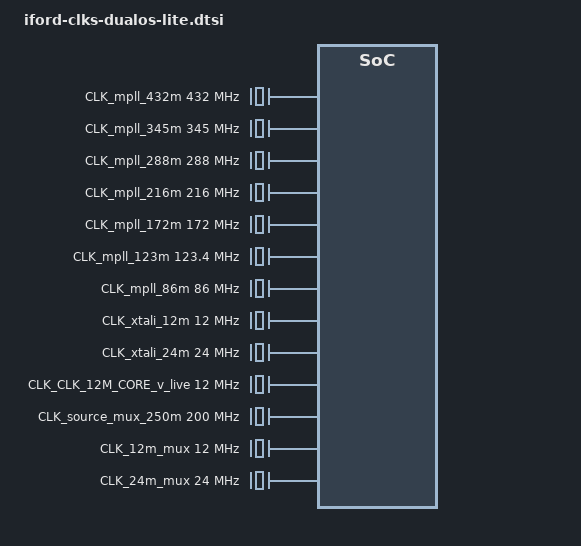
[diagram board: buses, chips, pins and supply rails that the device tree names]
/*
* iford-clks.dtsi- Sigmastar
*
* Copyright (c) [2019~2020] SigmaStar Technology.
*
*
* This software is licensed under the terms of the GNU General Public
* License version 2, as published by the Free Software Foundation, and
* may be copied, distributed, and modified under those terms.
*
* This program is distributed in the hope that it will be useful,
* but WITHOUT ANY WARRANTY; without even the implied warranty of
* MERCHANTABILITY or FITNESS FOR A PARTICULAR PURPOSE.  See the
* GNU General Public License version 2 for more details.
*
*/

/* generated by CLK_DT_GEN_5.2 */
/* CLK FILENAME: iford\iford_clock_table.xls */
/* REG FILENAME: iford\iford_reg_CLKGEN.xls, ifordw\iford_reg_CLKGEN2.xls, iford\iford_reg_pm_sleep.xls, iford\iford_reg_block.xls, iford\ifordw_reg_chiptop.xls */

CLK_VOID: CLK_VOID {
    #clock-cells = <0>;
    compatible = "fixed-clock";
    clock-frequency = <1>;
};

CLK_upll_480m: CLK_upll_480m {
    #clock-cells = <0>;
    compatible = "sstar,complex-clock";
    clocks = <&CLK_upll_960m>;
};

CLK_mpll_432m: CLK_mpll_432m {
    #clock-cells = <0>;
    compatible = "fixed-clock";
    clock-frequency = <432000000>;
};

CLK_upll_384m: CLK_upll_384m {
    #clock-cells = <0>;
    compatible = "sstar,complex-clock";
    clocks = <&CLK_upll_960m>;
};

CLK_mpll_345m: CLK_mpll_345m {
    #clock-cells = <0>;
    compatible = "fixed-clock";
    clock-frequency = <345000000>;
};

CLK_upll_320m: CLK_upll_320m {
    #clock-cells = <0>;
    compatible = "sstar,complex-clock";
    clocks = <&CLK_upll_960m>;
};

CLK_mpll_288m: CLK_mpll_288m {
    #clock-cells = <0>;
    compatible = "fixed-clock";
    clock-frequency = <288000000>;
};

CLK_mpll_216m: CLK_mpll_216m {
    #clock-cells = <0>;
    compatible = "fixed-clock";
    clock-frequency = <216000000>;
};

CLK_mpll_172m: CLK_mpll_172m {
    #clock-cells = <0>;
    compatible = "fixed-clock";
    clock-frequency = <172000000>;
};

CLK_mpll_123m: CLK_mpll_123m {
    #clock-cells = <0>;
    compatible = "fixed-clock";
    clock-frequency = <123400000>;
};

CLK_mpll_86m: CLK_mpll_86m {
    #clock-cells = <0>;
    compatible = "fixed-clock";
    clock-frequency = <86000000>;
};

CLK_upll_480m_div2: CLK_upll_480m_div2 {
    #clock-cells = <0>;
    compatible = "fixed-factor-clock";
    clocks = <&CLK_upll_480m>;
    clock-div = <2>;
    clock-mult = <1>;
};

CLK_upll_384m_div2: CLK_upll_384m_div2 {
    #clock-cells = <0>;
    compatible = "fixed-factor-clock";
    clocks = <&CLK_upll_384m>;
    clock-div = <2>;
    clock-mult = <1>;
};

CLK_upll_320m_div2: CLK_upll_320m_div2 {
    #clock-cells = <0>;
    compatible = "fixed-factor-clock";
    clocks = <&CLK_upll_320m>;
    clock-div = <2>;
    clock-mult = <1>;
};

CLK_mpll_288m_div2: CLK_mpll_288m_div2 {
    #clock-cells = <0>;
    compatible = "fixed-factor-clock";
    clocks = <&CLK_mpll_288m>;
    clock-div = <2>;
    clock-mult = <1>;
};

CLK_mpll_288m_div4: CLK_mpll_288m_div4 {
    #clock-cells = <0>;
    compatible = "fixed-factor-clock";
    clocks = <&CLK_mpll_288m>;
    clock-div = <4>;
    clock-mult = <1>;
};

CLK_mpll_288m_div8: CLK_mpll_288m_div8 {
    #clock-cells = <0>;
    compatible = "fixed-factor-clock";
    clocks = <&CLK_mpll_288m>;
    clock-div = <8>;
    clock-mult = <1>;
};

CLK_mpll_432m_div4: CLK_mpll_432m_div4 {
    #clock-cells = <0>;
    compatible = "fixed-factor-clock";
    clocks = <&CLK_mpll_432m>;
    clock-div = <4>;
    clock-mult = <1>;
};

CLK_mpll_432m_div8: CLK_mpll_432m_div8 {
    #clock-cells = <0>;
    compatible = "fixed-factor-clock";
    clocks = <&CLK_mpll_432m>;
    clock-div = <8>;
    clock-mult = <1>;
};

CLK_mpll_432m_div16: CLK_mpll_432m_div16 {
    #clock-cells = <0>;
    compatible = "fixed-factor-clock";
    clocks = <&CLK_mpll_432m>;
    clock-div = <16>;
    clock-mult = <1>;
};

CLK_mpll_123m_div2: CLK_mpll_123m_div2 {
    #clock-cells = <0>;
    compatible = "fixed-factor-clock";
    clocks = <&CLK_mpll_123m>;
    clock-div = <2>;
    clock-mult = <1>;
};

CLK_mpll_86m_div2: CLK_mpll_86m_div2 {
    #clock-cells = <0>;
    compatible = "fixed-factor-clock";
    clocks = <&CLK_mpll_86m>;
    clock-div = <2>;
    clock-mult = <1>;
};

CLK_mpll_86m_div4: CLK_mpll_86m_div4 {
    #clock-cells = <0>;
    compatible = "fixed-factor-clock";
    clocks = <&CLK_mpll_86m>;
    clock-div = <4>;
    clock-mult = <1>;
};

CLK_mpll_86m_div16: CLK_mpll_86m_div16 {
    #clock-cells = <0>;
    compatible = "fixed-factor-clock";
    clocks = <&CLK_mpll_86m>;
    clock-div = <16>;
    clock-mult = <1>;
};

CLK_upll_384m_div8: CLK_upll_384m_div8 {
    #clock-cells = <0>;
    compatible = "fixed-factor-clock";
    clocks = <&CLK_upll_384m>;
    clock-div = <8>;
    clock-mult = <1>;
};

CLK_upll_320m_div8: CLK_upll_320m_div8 {
    #clock-cells = <0>;
    compatible = "fixed-factor-clock";
    clocks = <&CLK_upll_320m>;
    clock-div = <8>;
    clock-mult = <1>;
#if !IS_ENABLED(CONFIG_SSTAR_SDMMC)
    status = "disabled";
#endif
};

CLK_upll_320m_div10: CLK_upll_320m_div10 {
    #clock-cells = <0>;
    compatible = "fixed-factor-clock";
    clocks = <&CLK_upll_320m>;
    clock-div = <10>;
    clock-mult = <1>;
#if !IS_ENABLED(CONFIG_SSTAR_SDMMC)
    status = "disabled";
#endif
};

CLK_upll_320m_div16: CLK_upll_320m_div16 {
    #clock-cells = <0>;
    compatible = "fixed-factor-clock";
    clocks = <&CLK_upll_320m>;
    clock-div = <16>;
    clock-mult = <1>;
#if !IS_ENABLED(CONFIG_SSTAR_SDMMC)
    status = "disabled";
#endif

};

CLK_disppll_clk: CLK_disppll_clk {
    #clock-cells = <0>;
    compatible = "sstar,complex-clock";
    clocks = <&CLK_mpll_432m>;
};

CLK_disppll_clk_div2: CLK_disppll_clk_div2 {
    #clock-cells = <0>;
    compatible = "fixed-factor-clock";
    clocks = <&CLK_disppll_clk>;
    clock-div = <2>;
    clock-mult = <1>;
};

CLK_xtali_12m: CLK_xtali_12m {
    #clock-cells = <0>;
    compatible = "fixed-clock";
    clock-frequency = <12000000>;
};

CLK_xtali_12m_div8: CLK_xtali_12m_div8 {
    #clock-cells = <0>;
    compatible = "fixed-factor-clock";
    clocks = <&CLK_xtali_12m>;
    clock-div = <8>;
    clock-mult = <1>;
};

CLK_xtali_12m_div16: CLK_xtali_12m_div16 {
    #clock-cells = <0>;
    compatible = "fixed-factor-clock";
    clocks = <&CLK_xtali_12m>;
    clock-div = <16>;
    clock-mult = <1>;
};

CLK_xtali_12m_div40: CLK_xtali_12m_div40 {
    #clock-cells = <0>;
    compatible = "fixed-factor-clock";
    clocks = <&CLK_xtali_12m>;
    clock-div = <40>;
    clock-mult = <1>;
};

CLK_xtali_12m_div64: CLK_xtali_12m_div64 {
    #clock-cells = <0>;
    compatible = "fixed-factor-clock";
    clocks = <&CLK_xtali_12m>;
    clock-div = <64>;
    clock-mult = <1>;
};

CLK_xtali_12m_div128: CLK_xtali_12m_div128 {
    #clock-cells = <0>;
    compatible = "fixed-factor-clock";
    clocks = <&CLK_xtali_12m>;
    clock-div = <128>;
    clock-mult = <1>;
};

CLK_xtali_24m: CLK_xtali_24m {
    #clock-cells = <0>;
    compatible = "fixed-clock";
    clock-frequency = <24000000>;
};

CLK_CLK_12M_CORE_v_live: CLK_CLK_12M_CORE_v_live {
    #clock-cells = <0>;
    compatible = "fixed-clock";
    clock-frequency = <12000000>;
};

CLK_ipupll_clk: CLK_ipupll_clk {
    #clock-cells = <0>;
    compatible = "sstar,complex-clock";
    clocks = <&CLK_mpll_432m>;
};

CLK_miupll_clk: CLK_miupll_clk {
    #clock-cells = <0>;
    compatible = "sstar,complex-clock";
    clocks = <&CLK_xtali_24m>;
};

CLK_cpu_pll: CLK_cpu_pll {
    #clock-cells = <0>;
    compatible = "sstar,complex-clock";
    clocks = <&CLK_mpll_432m>;
};

CLK_armpll_37p125m: CLK_armpll_37p125m {
    #clock-cells = <0>;
    compatible = "sstar,complex-clock";
    clocks = <&CLK_cpu_pll>;
};

CLK_spi_synth_pll: CLK_spi_synth_pll {
    #clock-cells = <0>;
    compatible = "sstar,complex-clock";
    clocks = <&CLK_mpll_432m>;
};

CLK_fuart_synth_out: CLK_fuart_synth_out {
    #clock-cells = <0>;
    compatible = "sstar,complex-clock";
    clocks = <&CLK_fuart_synth_in>;
};

CLK_fuart0_synth_out: CLK_fuart0_synth_out {
    #clock-cells = <0>;
    compatible = "sstar,complex-clock";
    clocks = <&CLK_fuart0_synth_in>;
};

CLK_fuart1_synth_out: CLK_fuart1_synth_out {
    #clock-cells = <0>;
    compatible = "sstar,complex-clock";
    clocks = <&CLK_fuart1_synth_in>;
};

CLK_miu_p: CLK_miu_p {
    #clock-cells = <0>;
    compatible = "fixed-factor-clock";
    clocks = <&CLK_miupll_clk>;
    clock-div = <1>;
    clock-mult = <1>;
};

CLK_mspi0_p: CLK_mspi0_p {
    #clock-cells = <0>;
    compatible = "fixed-factor-clock";
    clocks = <&CLK_mspi0>;
    clock-div = <1>;
    clock-mult = <1>;
#if !IS_ENABLED(CONFIG_SSTAR_MSPI)
    status = "disabled";
#endif
};

CLK_mcu_p: CLK_mcu_p {
    #clock-cells = <0>;
    compatible = "fixed-factor-clock";
    clocks = <&CLK_mcu>;
    clock-div = <1>;
    clock-mult = <1>;
};

CLK_mcu_pm_p: CLK_mcu_pm_p {
    #clock-cells = <0>;
    compatible = "fixed-factor-clock";
    clocks = <&CLK_mcu_pm>;
    clock-div = <1>;
    clock-mult = <1>;
};

CLK_otp_p: CLK_otp_p {
    #clock-cells = <0>;
    compatible = "fixed-clock";
    clock-frequency = <12000000>;
};

CLK_bist_pm_p: CLK_bist_pm_p {
    #clock-cells = <0>;
    compatible = "fixed-clock";
    clock-frequency = <192000000>;
};

CLK_emac_testrx125_in_lan: CLK_emac_testrx125_in_lan {
    #clock-cells = <0>;
    compatible = "fixed-clock";
    clock-frequency = <125000000>;
};

CLK_source_mux_250m: CLK_source_mux_250m {
    #clock-cells = <0>;
#ifndef  CONFIG_PM_CLK_SRC_24M
    compatible = "fixed-clock";
    clock-frequency = <200000000>;
#else
    // select mpll-216 to replace rtcpll when remove RTC 32K xtal
    compatible = "fixed-factor-clock";
    clocks = <&CLK_mpll_216m>;
    clock-div = <1>;
    clock-mult = <1>;
#endif
};

CLK_source_mux_250m_div2: CLK_source_mux_250m_div2 {
    #clock-cells = <0>;
    compatible = "fixed-factor-clock";
    clocks = <&CLK_source_mux_250m>;
    clock-div = <2>;
    clock-mult = <1>;
};

CLK_source_mux_250m_div4: CLK_source_mux_250m_div4 {
    #clock-cells = <0>;
    compatible = "fixed-factor-clock";
    clocks = <&CLK_source_mux_250m>;
    clock-div = <4>;
    clock-mult = <1>;
};

CLK_source_mux_250m_div5: CLK_source_mux_250m_div5 {
    #clock-cells = <0>;
    compatible = "fixed-factor-clock";
    clocks = <&CLK_source_mux_250m>;
    clock-div = <5>;
    clock-mult = <1>;
};

CLK_source_mux_250m_div6: CLK_source_mux_250m_div6 {
    #clock-cells = <0>;
    compatible = "fixed-factor-clock";
    clocks = <&CLK_source_mux_250m>;
    clock-div = <6>;
    clock-mult = <1>;
};

CLK_source_mux_250m_div8: CLK_source_mux_250m_div8 {
    #clock-cells = <0>;
    compatible = "fixed-factor-clock";
    clocks = <&CLK_source_mux_250m>;
    clock-div = <8>;
    clock-mult = <1>;
};

CLK_12m_mux: CLK_12m_mux {
    #clock-cells = <0>;
    compatible = "fixed-clock";
    clock-frequency = <12000000>;
};

CLK_12m_mux_div2: CLK_12m_mux_div2 {
    #clock-cells = <0>;
    compatible = "fixed-factor-clock";
    clocks = <&CLK_12m_mux>;
    clock-div = <2>;
    clock-mult = <1>;
};

CLK_12m_mux_div40: CLK_12m_mux_div40 {
    #clock-cells = <0>;
    compatible = "fixed-factor-clock";
    clocks = <&CLK_12m_mux>;
    clock-div = <40>;
    clock-mult = <1>;
};

CLK_24m_mux: CLK_24m_mux {
    #clock-cells = <0>;
    compatible = "fixed-clock";
    clock-frequency = <24000000>;
};

CLK_ddr_syn: CLK_ddr_syn {
    #clock-cells = <0>;
    compatible = "sstar,composite-clock";
    clocks = <&CLK_mpll_432m>,<&CLK_mpll_216m>,<&CLK_xtali_12m>;
    reg = <REG_CKG_DDR_SYN_BASE 0x4>;
    mux-shift = <2>;  //2+REG_CKG_DDR_SYN_OFFSET
    mux-width = <2>;
    gate-shift = <0>;  //0+REG_CKG_DDR_SYN_OFFSET
    auto-enable = <1>;
};

CLK_miu_rec: CLK_miu_rec {
    #clock-cells = <0>;
    compatible = "sstar,composite-clock";
    clocks = <&CLK_xtali_12m_div8>,<&CLK_xtali_12m_div16>,<&CLK_xtali_12m_div64>,<&CLK_xtali_12m_div128>;
    reg = <REG_CKG_MIU_REC_BASE 0x4>;
    mux-shift = <2>;  //2+REG_CKG_MIU_REC_OFFSET
    mux-width = <2>;
    gate-shift = <0>;  //0+REG_CKG_MIU_REC_OFFSET
    auto-enable = <1>;
};

CLK_mcu: CLK_mcu {
    #clock-cells = <0>;
    compatible = "sstar,composite-clock";
    clocks = <&CLK_mpll_216m>,<&CLK_mpll_288m>,<&CLK_upll_320m>,<&CLK_mpll_432m_div4>,<&CLK_xtali_12m>;
    reg = <REG_CKG_MCU_BASE 0x4>;
    mux-shift = <2>;  //2+REG_CKG_MCU_OFFSET
    mux-width = <2>;
    gate-shift = <0>;  //0+REG_CKG_MCU_OFFSET
    glitch-shift = <4>;  //4+REG_CKG_MCU_OFFSET
    str-ignore;
    auto-enable = <1>;
};

CLK_riubrdg: CLK_riubrdg {
    #clock-cells = <0>;
    compatible = "sstar,composite-clock";
    clocks = <&CLK_mcu_p>;
    reg = <REG_CKG_RIUBRDG_BASE 0x4>;
    mux-shift = <10>;  //2+REG_CKG_RIUBRDG_OFFSET
    mux-width = <2>;
    gate-shift = <8>;  //0+REG_CKG_RIUBRDG_OFFSET
    auto-enable = <1>;
};

CLK_pwm: CLK_pwm {
    #clock-cells = <0>;
    compatible = "sstar,composite-clock";
    clocks = <&CLK_xtali_12m>;
    reg = <REG_CKG_PWM_BASE 0x4>;
    mux-shift = <10>;  //2+REG_CKG_PWM_OFFSET
    mux-width = <3>;
    gate-shift = <8>;  //0+REG_CKG_PWM_OFFSET
    ignore = <1>;
};

CLK_fuart_synth_in: CLK_fuart_synth_in {
    #clock-cells = <0>;
    compatible = "sstar,composite-clock";
    clocks = <&CLK_mpll_432m>,<&CLK_mpll_216m>;
    reg = <REG_CKG_FUART_SYNTH_IN_BASE 0x4>;
    mux-shift = <6>;  //2+REG_CKG_FUART_SYNTH_IN_OFFSET
    mux-width = <2>;
    gate-shift = <4>;  //0+REG_CKG_FUART_SYNTH_IN_OFFSET
    auto-enable = <0>;
};

CLK_fuart0_synth_in: CLK_fuart0_synth_in {
    #clock-cells = <0>;
    compatible = "sstar,composite-clock";
    clocks = <&CLK_mpll_432m>,<&CLK_mpll_216m>;
    reg = <REG_CKG_FUART0_SYNTH_IN_BASE 0x4>;
    mux-shift = <6>;  //2+REG_CKG_FUART0_SYNTH_IN_OFFSET
    mux-width = <2>;
    gate-shift = <4>;  //0+REG_CKG_FUART0_SYNTH_IN_OFFSET
    auto-enable = <0>;
};

CLK_fuart1_synth_in: CLK_fuart1_synth_in {
    #clock-cells = <0>;
    compatible = "sstar,composite-clock";
    clocks = <&CLK_mpll_432m>,<&CLK_mpll_216m>;
    reg = <REG_CKG_FUART1_SYNTH_IN_BASE 0x4>;
    mux-shift = <6>;  //2+REG_CKG_FUART1_SYNTH_IN_OFFSET
    mux-width = <2>;
    gate-shift = <4>;  //0+REG_CKG_FUART1_SYNTH_IN_OFFSET
    auto-enable = <0>;
};

CLK_fuart: CLK_fuart {
    #clock-cells = <0>;
    compatible = "sstar,composite-clock";
    clocks = <&CLK_mpll_172m>,<&CLK_mpll_288m_div2>,<&CLK_xtali_24m>,<&CLK_fuart_synth_out>;
    reg = <REG_CKG_FUART_BASE 0x4>;
    mux-shift = <2>;  //2+REG_CKG_FUART_OFFSET
    mux-width = <2>;
    gate-shift = <0>;  //0+REG_CKG_FUART_OFFSET
    auto-enable = <0>;
};

CLK_fuart0: CLK_fuart0 {
    #clock-cells = <0>;
    compatible = "sstar,composite-clock";
    clocks = <&CLK_mpll_172m>,<&CLK_mpll_288m_div2>,<&CLK_xtali_24m>,<&CLK_fuart0_synth_out>;
    reg = <REG_CKG_FUART0_BASE 0x4>;
    mux-shift = <2>;  //2+REG_CKG_FUART0_OFFSET
    mux-width = <2>;
    gate-shift = <0>;  //0+REG_CKG_FUART0_OFFSET
    auto-enable = <1>;
};

CLK_fuart1: CLK_fuart1 {
    #clock-cells = <0>;
    compatible = "sstar,composite-clock";
    clocks = <&CLK_mpll_172m>,<&CLK_mpll_288m_div2>,<&CLK_xtali_24m>,<&CLK_fuart1_synth_out>;
    reg = <REG_CKG_FUART1_BASE 0x4>;
    mux-shift = <6>;  //2+REG_CKG_FUART1_OFFSET
    mux-width = <2>;
    gate-shift = <4>;  //0+REG_CKG_FUART1_OFFSET
    auto-enable = <0>;
};

CLK_mspi0: CLK_mspi0 {
    #clock-cells = <0>;
    compatible = "sstar,composite-clock";
    clocks = <&CLK_mpll_432m_div4>,<&CLK_mpll_288m_div2>,<&CLK_xtali_12m>,<&CLK_spi_synth_pll>;
    reg = <REG_CKG_MSPI0_BASE 0x4>;
    mux-shift = <2>;  //2+REG_CKG_MSPI0_OFFSET
    mux-width = <2>;
    gate-shift = <0>;  //0+REG_CKG_MSPI0_OFFSET
    auto-enable = <0>;
#if !IS_ENABLED(CONFIG_SSTAR_MSPI)
    status = "disabled";
#endif
};

CLK_miic0: CLK_miic0 {
    #clock-cells = <0>;
    compatible = "sstar,composite-clock";
    clocks = <&CLK_mpll_288m_div4>,<&CLK_mpll_432m_div8>,<&CLK_xtali_12m>;
    reg = <REG_CKG_MIIC0_BASE 0x4>;
    mux-shift = <2>;  //2+REG_CKG_MIIC0_OFFSET
    mux-width = <2>;
    gate-shift = <0>;  //0+REG_CKG_MIIC0_OFFSET
    auto-enable = <0>;
};

CLK_miic1: CLK_miic1 {
    #clock-cells = <0>;
    compatible = "sstar,composite-clock";
    clocks = <&CLK_mpll_288m_div4>,<&CLK_mpll_432m_div8>,<&CLK_xtali_12m>;
    reg = <REG_CKG_MIIC1_BASE 0x4>;
    mux-shift = <10>;  //2+REG_CKG_MIIC1_OFFSET
    mux-width = <2>;
    gate-shift = <8>;  //0+REG_CKG_MIIC1_OFFSET
    auto-enable = <0>;
};

CLK_miic2: CLK_miic2 {
    #clock-cells = <0>;
    compatible = "sstar,composite-clock";
    clocks = <&CLK_mpll_288m_div4>,<&CLK_mpll_432m_div8>,<&CLK_xtali_12m>;
    reg = <REG_CKG_MIIC2_BASE 0x4>;
    mux-shift = <14>;  //2+REG_CKG_MIIC2_OFFSET
    mux-width = <2>;
    gate-shift = <12>;  //0+REG_CKG_MIIC2_OFFSET
    auto-enable = <0>;
};

CLK_pwr_ctl: CLK_pwr_ctl {
    #clock-cells = <0>;
    compatible = "sstar,composite-clock";
    clocks = <&CLK_xtali_12m_div16>,<&CLK_xtali_12m_div8>,<&CLK_xtali_12m>;
    reg = <REG_CKG_PWR_CTL_BASE 0x4>;
    mux-shift = <2>;  //2+REG_CKG_PWR_CTL_OFFSET
    mux-width = <2>;
    gate-shift = <0>;  //0+REG_CKG_PWR_CTL_OFFSET
    auto-enable = <1>;
};

CLK_xtali: CLK_xtali {
    #clock-cells = <0>;
    compatible = "sstar,composite-clock";
    clocks = <&CLK_xtali_12m>;
    reg = <REG_CKG_XTALI_BASE 0x4>;
    mux-shift = <2>;  //2+REG_CKG_XTALI_OFFSET
    mux-width = <2>;
    gate-shift = <0>;  //0+REG_CKG_XTALI_OFFSET
    auto-enable = <1>;
};

CLK_live_c: CLK_live_c {
    #clock-cells = <0>;
    compatible = "sstar,composite-clock";
    clocks = <&CLK_xtali_12m>;
    reg = <REG_CKG_LIVE_BASE 0x4>;
    mux-shift = <10>;  //2+REG_CKG_LIVE_OFFSET
    mux-width = <2>;
    gate-shift = <8>;  //0+REG_CKG_LIVE_OFFSET
    auto-enable = <1>;
};

CLK_live: CLK_live {
    #clock-cells = <0>;
    compatible = "sstar,composite-clock";
    clocks = <&CLK_xtali_12m>;
    reg = <REG_CKG_LIVE_BASE 0x4>;
    mux-shift = <10>;  //2+REG_CKG_LIVE_OFFSET
    mux-width = <2>;
    gate-shift = <8>;  //0+REG_CKG_LIVE_OFFSET
    auto-enable = <1>;
};

CLK_sr00_mclk: CLK_sr00_mclk {
    #clock-cells = <0>;
    compatible = "sstar,composite-clock";
    clocks = <&CLK_mpll_432m_div16>,<&CLK_mpll_288m_div4>,<&CLK_mpll_123m_div2>,<&CLK_mpll_432m_div8>,<&CLK_upll_384m_div8>,<&CLK_mpll_86m_div2>,<&CLK_mpll_288m_div8>,<&CLK_xtali_24m>,<&CLK_mpll_86m_div4>,<&CLK_xtali_12m>,<&CLK_mpll_86m_div16>,<&CLK_armpll_37p125m>;
    reg = <REG_CKG_SR00_MCLK_BASE 0x4>, <REG_CLK_SR00_MCLK_DFS_EN_BASE 0x4>;
    mux-shift = <10>;  //2+REG_CKG_SR00_MCLK_OFFSET
    mux-width = <4>;
    gate-shift = <8>;  //0+REG_CKG_SR00_MCLK_OFFSET
    dfs-shift = <8>;  //0+REG_CLK_SR00_MCLK_DFS_EN_BASE
    dfs-width = <5>;
    auto-enable = <0>;
};

CLK_sr01_mclk: CLK_sr01_mclk {
    #clock-cells = <0>;
    compatible = "sstar,composite-clock";
    clocks = <&CLK_mpll_432m_div16>,<&CLK_mpll_288m_div4>,<&CLK_mpll_123m_div2>,<&CLK_mpll_432m_div8>,<&CLK_upll_384m_div8>,<&CLK_mpll_86m_div2>,<&CLK_mpll_288m_div8>,<&CLK_xtali_24m>,<&CLK_mpll_86m_div4>,<&CLK_xtali_12m>,<&CLK_mpll_86m_div16>,<&CLK_armpll_37p125m>;
    reg = <REG_CKG_SR01_MCLK_BASE 0x4>, <REG_CLK_SR01_MCLK_DFS_EN_BASE 0x4>;
    mux-shift = <2>;  //2+REG_CKG_SR01_MCLK_OFFSET
    mux-width = <4>;
    gate-shift = <0>;  //0+REG_CKG_SR01_MCLK_OFFSET
    dfs-shift = <8>;  //0+REG_CLK_SR01_MCLK_DFS_EN_BASE
    dfs-width = <5>;
    auto-enable = <0>;
};

CLK_ipu: CLK_ipu {
    #clock-cells = <0>;
    compatible = "sstar,composite-clock";
    clocks = <&CLK_xtali_12m>,<&CLK_upll_320m>,<&CLK_mpll_432m>,<&CLK_upll_480m>;
    reg = <REG_CKG_IPU_BASE 0x4>;
    mux-shift = <2>;  //2+REG_CKG_IPU_OFFSET
    mux-width = <2>;
    gate-shift = <0>;  //0+REG_CKG_IPU_OFFSET
    auto-enable = <0>;
};

CLK_ipuff: CLK_ipuff {
    #clock-cells = <0>;
    compatible = "sstar,composite-clock";
    clocks = <&CLK_mpll_432m>,<&CLK_upll_320m>,<&CLK_mpll_288m>,<&CLK_mpll_216m>;
    reg = <REG_CKG_IPUFF_BASE 0x4>;
    mux-shift = <10>;  //2+REG_CKG_IPUFF_OFFSET
    mux-width = <2>;
    gate-shift = <8>;  //0+REG_CKG_IPUFF_OFFSET
    auto-enable = <0>;
};

CLK_hemcu: CLK_hemcu {
    #clock-cells = <0>;
    compatible = "sstar,composite-clock";
    clocks = <&CLK_mpll_432m>,<&CLK_mpll_216m>;
    reg = <REG_CKG_HEMCU_BASE 0x4>;
    mux-shift = <2>;  //2+REG_CKG_HEMCU_OFFSET
    mux-width = <2>;
    gate-shift = <0>;  //0+REG_CKG_HEMCU_OFFSET
    auto-enable = <0>;
};

CLK_csi0_mac_lptx_top_i: CLK_csi0_mac_lptx_top_i {
    #clock-cells = <0>;
    compatible = "sstar,composite-clock";
    clocks = <&CLK_mpll_432m>,<&CLK_mpll_288m>,<&CLK_upll_320m>,<&CLK_mpll_172m>;
    reg = <REG_CKG_CSI0_MAC_LPTX_TOP_I_BASE 0x4>, <REG_CLK_CSI0_MAC_LPTX_DFS_EN_BASE 0x4>;
    mux-shift = <2>;  //2+REG_CKG_CSI0_MAC_LPTX_TOP_I_OFFSET
    mux-width = <2>;
    gate-shift = <0>;  //0+REG_CKG_CSI0_MAC_LPTX_TOP_I_OFFSET
    dfs-shift = <8>;  //0+REG_CLK_CSI0_MAC_LPTX_DFS_EN_BASE
    dfs-width = <5>;
    ignore = <1>;
};

CLK_csi0_mac_top_i: CLK_csi0_mac_top_i {
    #clock-cells = <0>;
    compatible = "sstar,composite-clock";
    clocks = <&CLK_mpll_432m>,<&CLK_mpll_288m>,<&CLK_upll_320m>,<&CLK_mpll_172m>;
    reg = <REG_CKG_CSI0_MAC_TOP_I_BASE 0x4>, <REG_CLK_CSI0_MAC_TOP_I_DFS_EN_BASE 0x4>;
    mux-shift = <10>;  //2+REG_CKG_CSI0_MAC_TOP_I_OFFSET
    mux-width = <2>;
    gate-shift = <8>;  //0+REG_CKG_CSI0_MAC_TOP_I_OFFSET
    dfs-shift = <0>;  //0+REG_CLK_CSI0_MAC_TOP_I_DFS_EN_BASE
    dfs-width = <5>;
    ignore = <1>;
};

CLK_csi0_ns_top_i: CLK_csi0_ns_top_i {
    #clock-cells = <0>;
    compatible = "sstar,composite-clock";
    clocks = <&CLK_mpll_432m>,<&CLK_mpll_288m>,<&CLK_upll_320m>,<&CLK_mpll_172m>;
    reg = <REG_CKG_CSI0_NS_TOP_I_BASE 0x4>, <REG_CLK_CSI0_NS_TOP_I_DFS_EN_BASE 0x4>;
    mux-shift = <2>;  //2+REG_CKG_CSI0_NS_TOP_I_OFFSET
    mux-width = <2>;
    gate-shift = <0>;  //0+REG_CKG_CSI0_NS_TOP_I_OFFSET
    dfs-shift = <8>;  //0+REG_CLK_CSI0_NS_TOP_I_DFS_EN_BASE
    dfs-width = <5>;
    ignore = <1>;
};

CLK_csi1_mac_lptx_top_i: CLK_csi1_mac_lptx_top_i {
    #clock-cells = <0>;
    compatible = "sstar,composite-clock";
    clocks = <&CLK_mpll_432m>,<&CLK_mpll_288m>,<&CLK_upll_320m>,<&CLK_mpll_172m>;
    reg = <REG_CKG_CSI1_MAC_LPTX_TOP_I_BASE 0x4>, <REG_CLK_CSI1_MAC_LPTX_DFS_EN_BASE 0x4>;
    mux-shift = <10>;  //2+REG_CKG_CSI1_MAC_LPTX_TOP_I_OFFSET
    mux-width = <2>;
    gate-shift = <8>;  //0+REG_CKG_CSI1_MAC_LPTX_TOP_I_OFFSET
    dfs-shift = <8>;  //0+REG_CLK_CSI1_MAC_LPTX_DFS_EN_BASE
    dfs-width = <5>;
    ignore = <1>;
};

CLK_csi1_mac_top_i: CLK_csi1_mac_top_i {
    #clock-cells = <0>;
    compatible = "sstar,composite-clock";
    clocks = <&CLK_mpll_432m>,<&CLK_mpll_288m>,<&CLK_upll_320m>,<&CLK_mpll_172m>;
    reg = <REG_CKG_CSI1_MAC_TOP_I_BASE 0x4>, <REG_CLK_CSI1_MAC_TOP_I_DFS_EN_BASE 0x4>;
    mux-shift = <2>;  //2+REG_CKG_CSI1_MAC_TOP_I_OFFSET
    mux-width = <2>;
    gate-shift = <0>;  //0+REG_CKG_CSI1_MAC_TOP_I_OFFSET
    dfs-shift = <8>;  //0+REG_CLK_CSI1_MAC_TOP_I_DFS_EN_BASE
    dfs-width = <5>;
    ignore = <1>;
};

CLK_csi1_ns_top_i: CLK_csi1_ns_top_i {
    #clock-cells = <0>;
    compatible = "sstar,composite-clock";
    clocks = <&CLK_mpll_432m>,<&CLK_mpll_288m>,<&CLK_upll_320m>,<&CLK_mpll_172m>;
    reg = <REG_CKG_CSI1_NS_TOP_I_BASE 0x4>, <REG_CLK_CSI1_NS_TOP_I_DFS_EN_BASE 0x4>;
    mux-shift = <10>;  //2+REG_CKG_CSI1_NS_TOP_I_OFFSET
    mux-width = <2>;
    gate-shift = <8>;  //0+REG_CKG_CSI1_NS_TOP_I_OFFSET
    dfs-shift = <0>;  //0+REG_CLK_CSI1_NS_TOP_I_DFS_EN_BASE
    dfs-width = <5>;
    ignore = <1>;
};

CLK_vhe: CLK_vhe {
    #clock-cells = <0>;
    compatible = "sstar,composite-clock";
    clocks = <&CLK_mpll_216m>,<&CLK_upll_480m_div2>,<&CLK_mpll_345m>,<&CLK_upll_384m>,<&CLK_mpll_432m>,<&CLK_upll_480m>,<&CLK_mpll_288m>,<&CLK_upll_384m_div2>;
    reg = <REG_CKG_VHE_BASE 0x4>, <REG_CLK_VHE0_DFS_EN_BASE 0x4>;
    mux-shift = <2>;  //2+REG_CKG_VHE_OFFSET
    mux-width = <3>;
    od-shift = <4>;
    nonod-shift = <2>;
    gate-shift = <7>;  //0+REG_CKG_VHE_OFFSET
    dfs-shift = <0>;  //0+REG_CLK_VHE0_DFS_EN_BASE
    dfs-width = <5>;
    auto-enable = <1>;
};

CLK_mfe: CLK_mfe {
    #clock-cells = <0>;
    compatible = "sstar,composite-clock";
    clocks = <&CLK_mpll_288m>,<&CLK_upll_320m>,<&CLK_mpll_432m>,<&CLK_upll_480m>,<&CLK_mpll_216m>,<&CLK_upll_384m>,<&CLK_mpll_345m>,<&CLK_mpll_288m_div2>;
    reg = <REG_CKG_MFE_BASE 0x4>, <REG_CLK_MFE0_DFS_EN_BASE 0x4>;
    mux-shift = <2>;  //2+REG_CKG_MFE_OFFSET
    mux-width = <3>;
    od-shift = <3>;
    nonod-shift = <2>;
    gate-shift = <0>;  //0+REG_CKG_MFE_OFFSET
    dfs-shift = <0>;  //0+REG_CLK_MFE0_DFS_EN_BASE
    dfs-width = <5>;
    auto-enable = <0>;
};

CLK_ven_axi: CLK_ven_axi {
    #clock-cells = <0>;
    compatible = "sstar,composite-clock";
    clocks = <&CLK_mpll_216m>,<&CLK_upll_480m_div2>,<&CLK_mpll_345m>,<&CLK_upll_384m>,<&CLK_mpll_432m>,<&CLK_upll_480m>,<&CLK_mpll_288m>,<&CLK_upll_384m_div2>;
    reg = <REG_CKG_VEN_AXI_BASE 0x4>, <REG_CLK_VEN0_AXI_DFS_EN_BASE 0x4>;
    mux-shift = <10>;  //2+REG_CKG_VEN_AXI_OFFSET
    mux-width = <3>;
    od-shift = <4>;
    nonod-shift = <2>;
    gate-shift = <8>;  //0+REG_CKG_VEN_AXI_OFFSET
    dfs-shift = <8>;  //0+REG_CLK_VEN0_AXI_DFS_EN_BASE
    dfs-width = <5>;
    auto-enable = <0>;
};

CLK_ven_scdn: CLK_ven_scdn {
    #clock-cells = <0>;
    compatible = "sstar,composite-clock";
    clocks = <&CLK_mpll_216m>,<&CLK_upll_480m_div2>,<&CLK_mpll_345m>,<&CLK_upll_384m>,<&CLK_mpll_432m>,<&CLK_upll_480m>,<&CLK_mpll_288m>,<&CLK_upll_384m_div2>;
    reg = <REG_CKG_VEN_SCDN_BASE 0x4>, <REG_CLK_VEN0_SCDN_DFS_EN_BASE 0x4>;
    mux-shift = <2>;  //2+REG_CKG_VEN_SCDN_OFFSET
    mux-width = <3>;
    od-shift = <4>;
    nonod-shift = <2>;
    gate-shift = <0>;  //0+REG_CKG_VEN_SCDN_OFFSET
    dfs-shift = <0>;  //0+REG_CLK_VEN0_SCDN_DFS_EN_BASE
    dfs-width = <5>;
    auto-enable = <0>;
};

CLK_ven_sc_if: CLK_ven_sc_if {
    #clock-cells = <0>;
    compatible = "sstar,composite-clock";
    clocks = <&CLK_mpll_432m_div4>,<&CLK_mpll_123m>,<&CLK_mpll_216m>,<&CLK_mpll_86m>;
    reg = <REG_CKG_VEN_SC_IF_BASE 0x4>, <REG_CLK_VEN0_SC_IF_DFS_EN_BASE 0x4>;
    mux-shift = <10>;  //2+REG_CKG_VEN_SC_IF_OFFSET
    mux-width = <2>;
    gate-shift = <8>;  //0+REG_CKG_VEN_SC_IF_OFFSET
    dfs-shift = <8>;  //0+REG_CLK_VEN0_SC_IF_DFS_EN_BASE
    dfs-width = <5>;
    auto-enable = <0>;
};

CLK_xtali_sc_gp: CLK_xtali_sc_gp {
    #clock-cells = <0>;
    compatible = "sstar,composite-clock";
    clocks = <&CLK_xtali_12m>;
    reg = <REG_CKG_XTALI_SC_GP_BASE 0x4>;
    mux-shift = <6>;  //2+REG_CKG_XTALI_SC_GP_OFFSET
    mux-width = <2>;
    gate-shift = <4>;  //0+REG_CKG_XTALI_SC_GP_OFFSET
    auto-enable = <1>;
};

CLK_jpe: CLK_jpe {
    #clock-cells = <0>;
    compatible = "sstar,composite-clock";
    clocks = <&CLK_mpll_216m>,<&CLK_upll_480m_div2>,<&CLK_mpll_288m>,<&CLK_upll_384m_div2>;
    reg = <REG_CKG_JPE_BASE 0x4>, <REG_CLK_JPE_DFS_EN_BASE 0x4>;
    mux-shift = <2>;  //2+REG_CKG_JPE_OFFSET
    mux-width = <2>;
    gate-shift = <0>;  //0+REG_CKG_JPE_OFFSET
    dfs-shift = <0>;  //0+REG_CLK_JPE_DFS_EN_BASE
    dfs-width = <5>;
    auto-enable = <0>;
};

CLK_aesdma: CLK_aesdma {
    #clock-cells = <0>;
    compatible = "sstar,composite-clock";
    clocks = <&CLK_miupll_clk>,<&CLK_mpll_216m>,<&CLK_mpll_172m>,<&CLK_otp_p>,<&CLK_xtali_12m>;
    reg = <REG_CKG_AESDMA_BASE 0x4>, <REG_CLK_AESDMA_DFS_EN_BASE 0x4>;
    mux-shift = <2>;  //2+REG_CKG_AESDMA_OFFSET
    mux-width = <2>;
    gate-shift = <0>;  //0+REG_CKG_AESDMA_OFFSET
    glitch-shift = <4>;  //4+REG_CKG_AESDMA_OFFSET
    dfs-shift = <0>;  //0+REG_CLK_AESDMA_DFS_EN_BASE
    dfs-width = <5>;
    auto-enable = <0>;
};


CLK_sd: CLK_sd {
    #clock-cells = <0>;
    compatible = "sstar,composite-clock";
    clocks = <&CLK_upll_384m_div8>,<&CLK_mpll_86m_div2>,<&CLK_upll_320m_div8>,<&CLK_mpll_288m_div8>,<&CLK_upll_320m_div10>,<&CLK_upll_320m_div16>,<&CLK_xtali_12m>,<&CLK_xtali_12m_div40>,<&CLK_spi_synth_pll>,<&CLK_mpll_432m>,<&CLK_upll_384m>,<&CLK_upll_320m>,<&CLK_mpll_288m>,<&CLK_mpll_216m>,<&CLK_mpll_432m_div4>,<&CLK_mpll_86m>,<&CLK_xtali_12m>;
    reg = <REG_CKG_SD_BASE 0x4>;
    mux-shift = <2>;  //2+REG_CKG_SD_OFFSET
    mux-width = <4>;
    gate-shift = <0>;  //0+REG_CKG_SD_OFFSET
    glitch-shift = <6>;  //6+REG_CKG_SD_OFFSET
    auto-enable = <0>;
#if !IS_ENABLED(CONFIG_SSTAR_SDMMC)
    status = "disabled";
#endif
};

CLK_fsp_qspi: CLK_fsp_qspi {
    #clock-cells = <0>;
    compatible = "sstar,composite-clock";
    clocks = <&CLK_spi_nonpm>,<&CLK_spi_synth_pll>;
    reg = <REG_CKG_SPI 0x4>;
    mux-shift = <2>;  //2+REG_CKG_SPI
    mux-width = <2>;
    gate-shift = <0>;  //0+REG_CKG_SPI
    glitch-shift = <4>;  //4+REG_CKG_SPI
    auto-enable = <0>;
};

CLK_bist_isp_gp: CLK_bist_isp_gp {
    #clock-cells = <0>;
    compatible = "sstar,composite-clock";
    clocks = <&CLK_mpll_216m>,<&CLK_mpll_123m>,<&CLK_mpll_288m_div2>,<&CLK_xtali_12m>;
    reg = <REG_CKG_BIST_ISP_GP_BASE 0x4>;
    mux-shift = <6>;  //2+REG_CKG_BIST_ISP_GP_OFFSET
    mux-width = <2>;
    gate-shift = <4>;  //0+REG_CKG_BIST_ISP_GP_OFFSET
    auto-enable = <0>;
};

CLK_isp: CLK_isp {
    #clock-cells = <0>;
    compatible = "sstar,composite-clock";
    clocks = <&CLK_mpll_288m>,<&CLK_upll_480m_div2>,<&CLK_upll_384m_div2>,<&CLK_upll_320m>;
    reg = <REG_CKG_ISP_BASE 0x4>, <REG_CLK_ISP_DFS_EN_BASE 0x4>;
    mux-shift = <10>;  //2+REG_CKG_ISP_OFFSET
    mux-width = <2>;
    od-shift = <3>;
    nonod-shift = <0>;
    gate-shift = <8>;  //0+REG_CKG_ISP_OFFSET
    dfs-shift = <0>;  //0+REG_CLK_ISP_DFS_EN_BASE
    dfs-width = <5>;
    ignore = <1>;
};

CLK_dsc_enc1: CLK_dsc_enc1 {
    #clock-cells = <0>;
    compatible = "sstar,composite-clock";
    clocks = <&CLK_upll_384m_div2>,<&CLK_upll_320m_div2>,<&CLK_mpll_288m_div2>,<&CLK_mpll_216m>;
    reg = <REG_CKG_DSC_ENC1_BASE 0x4>, <REG_CLK_DSC_ENC1_DFS_EN_BASE 0x4>;
    mux-shift = <10>;  //2+REG_CKG_DSC_ENC1_OFFSET
    mux-width = <2>;
    od-shift = <3>;
    nonod-shift = <0>;
    gate-shift = <8>;  //0+REG_CKG_DSC_ENC1_OFFSET
    dfs-shift = <8>;  //0+REG_CLK_DSC_ENC1_DFS_EN_BASE
    dfs-width = <5>;
    auto-enable = <0>;
};

CLK_dsc_dec1: CLK_dsc_dec1 {
    #clock-cells = <0>;
    compatible = "sstar,composite-clock";
    clocks = <&CLK_upll_384m_div2>,<&CLK_upll_320m_div2>,<&CLK_mpll_288m_div2>,<&CLK_mpll_216m>;
    reg = <REG_CKG_DSC_DEC1_BASE 0x4>, <REG_CLK_DSC_DEC1_DFS_EN_BASE 0x4>;
    mux-shift = <10>;  //2+REG_CKG_DSC_DEC1_OFFSET
    mux-width = <2>;
    od-shift = <3>;
    nonod-shift = <0>;
    gate-shift = <8>;  //0+REG_CKG_DSC_DEC1_OFFSET
    dfs-shift = <8>;  //0+REG_CLK_DSC_DEC1_DFS_EN_BASE
    dfs-width = <5>;
    auto-enable = <0>;
};

CLK_fclk1: CLK_fclk1 {
    #clock-cells = <0>;
    compatible = "sstar,composite-clock";
    clocks = <&CLK_mpll_288m>,<&CLK_upll_384m_div2>,<&CLK_mpll_288m_div2>,<&CLK_upll_320m>,<&CLK_upll_480m_div2>,<&CLK_mpll_216m>;
    reg = <REG_CKG_FCLK1_BASE 0x4>, <REG_CLK_SC_DFS_EN_BASE 0x4>;
    mux-shift = <2>;  //2+REG_CKG_FCLK1_OFFSET
    mux-width = <3>;
    od-shift = <3>;
    nonod-shift = <0>;
    gate-shift = <0>;  //0+REG_CKG_FCLK1_OFFSET
    dfs-shift = <0>;  //0+REG_CLK_SC_DFS_EN_BASE
    dfs-width = <5>;
    auto-enable = <0>;
};

CLK_disp_pixel_0: CLK_disp_pixel_0 {
    #clock-cells = <0>;
    compatible = "sstar,composite-clock";
    clocks = <&CLK_mpll_288m_div4>,<&CLK_mpll_432m_div8>,<&CLK_disppll_clk>,<&CLK_disppll_clk_div2>;
    reg = <REG_CKG_DISP_PIXEL_0_BASE 0x4>, <REG_CLK_DISP_PIXEL0_DFS_EN_BASE 0x4>;
    mux-shift = <2>;  //2+REG_CKG_DISP_PIXEL_0_OFFSET
    mux-width = <2>;
    gate-shift = <0>;  //0+REG_CKG_DISP_PIXEL_0_OFFSET
    dfs-shift = <0>;  //0+REG_CLK_DISP_PIXEL0_DFS_EN_BASE
    dfs-width = <5>;
    auto-enable = <0>;
};
CLK_ive: CLK_ive {
    #clock-cells = <0>;
    compatible = "sstar,composite-clock";
    clocks = <&CLK_mpll_288m>,<&CLK_mpll_216m>,<&CLK_upll_384m>,<&CLK_mpll_432m>;
    reg = <REG_CKG_IVE_BASE 0x4>, <REG_CLK_IVE_DFS_EN_BASE 0x4>;
    mux-shift = <10>;  //2+REG_CKG_IVE_OFFSET
    mux-width = <2>;
    od-shift = <3>;
    nonod-shift = <2>;
    gate-shift = <8>;  //0+REG_CKG_IVE_OFFSET
    dfs-shift = <0>;  //0+REG_CLK_IVE_DFS_EN_BASE
    dfs-width = <5>;
    auto-enable = <0>;
};
CLK_ldcfeye: CLK_ldcfeye {
    #clock-cells = <0>;
    compatible = "sstar,composite-clock";
    clocks = <&CLK_upll_384m>,<&CLK_mpll_216m>,<&CLK_mpll_172m>,<&CLK_mpll_123m>,<&CLK_mpll_432m>;
    reg = <REG_CKG_LDCFEYE_BASE 0x4>, <REG_CLK_LDCFEYE_DFS_EN_BASE 0x4>;
    mux-shift = <2>;  //2+REG_CKG_LDCFEYE_OFFSET
    mux-width = <3>;
    od-shift = <4>;
    nonod-shift = <0>;
    gate-shift = <0>;  //0+REG_CKG_LDCFEYE_OFFSET
    dfs-shift = <0>;  //0+REG_CLK_LDCFEYE_DFS_EN_BASE
    dfs-width = <5>;
    auto-enable = <0>;
};

CLK_emac_ahb: CLK_emac_ahb {
    #clock-cells = <0>;
    compatible = "sstar,composite-clock";
    clocks = <&CLK_mpll_288m_div2>,<&CLK_mpll_123m>,<&CLK_mpll_86m>,<&CLK_emac_testrx125_in_lan>;
    reg = <REG_CKG_EMAC_AHB_BASE 0x4>;
    mux-shift = <2>;  //2+REG_CKG_EMAC_AHB_OFFSET
    mux-width = <2>;
    gate-shift = <0>;  //0+REG_CKG_EMAC_AHB_OFFSET
    auto-enable = <1>;
};

CLK_au_sys_384: CLK_au_sys_384 {
    #clock-cells = <0>;
    compatible = "sstar,composite-clock";
    clocks = <&CLK_upll_384m>,<&CLK_upll_480m>,<&CLK_mpll_432m>;
    reg = <REG_CKG_AU_SYS_384_BASE 0x4>;
    mux-shift = <2>;  //2+REG_CKG_AU_SYS_384_OFFSET
    mux-width = <2>;
    gate-shift = <0>;  //0+REG_CKG_AU_SYS_384_OFFSET
    auto-enable = <0>;
};

CLK_au_sys_432: CLK_au_sys_432 {
    #clock-cells = <0>;
    compatible = "sstar,composite-clock";
    clocks = <&CLK_mpll_432m>,<&CLK_upll_480m>,<&CLK_upll_384m>;
    reg = <REG_CKG_AU_SYS_432_BASE 0x4>;
    mux-shift = <2>;  //2+REG_CKG_AU_SYS_432_OFFSET
    mux-width = <2>;
    gate-shift = <0>;  //0+REG_CKG_AU_SYS_432_OFFSET
    auto-enable = <0>;
};

CLK_otp: CLK_otp {
    #clock-cells = <0>;
    compatible = "sstar,composite-clock";
    clocks = <&CLK_xtali_12m>;
    reg = <REG_CKG_OTP_BASE 0x4>;
    mux-shift = <2>;  //2+REG_CKG_OTP_OFFSET
    mux-width = <2>;
    gate-shift = <0>;  //0+REG_CKG_OTP_OFFSET
    auto-enable = <1>;
};

CLK_real_live: CLK_real_live {
    #clock-cells = <0>;
    compatible = "sstar,composite-clock";
    clocks = <&CLK_CLK_12M_CORE_v_live>;
    reg = <REG_CKG_REAL_LIVE_BASE 0x4>;
    mux-shift = <2>;  //2+REG_CKG_REAL_LIVE_OFFSET
    mux-width = <2>;
    gate-shift = <0>;  //0+REG_CKG_REAL_LIVE_OFFSET
    auto-enable = <1>;
};

CLK_spi_nonpm: CLK_spi_nonpm {
    #clock-cells = <0>;
    compatible = "sstar,composite-clock";
    clocks = <&CLK_xtali_24m>,<&CLK_mpll_86m>,<&CLK_mpll_432m_div4>,<&CLK_mpll_432m_div8>;
    reg = <REG_CKG_SPI_NONPM_BASE 0x4>;
    mux-shift = <2>;  //2+REG_CKG_SPI_NONPM_OFFSET
    mux-width = <2>;
    gate-shift = <0>;  //0+REG_CKG_SPI_NONPM_OFFSET
    auto-enable = <1>;
};

CLK_pm_high_ext: CLK_pm_high_ext {
    #clock-cells = <0>;
    compatible = "sstar,composite-clock";
    clocks = <&CLK_upll_480m_div2>,<&CLK_mpll_216m>,<&CLK_upll_384m_div2>,<&CLK_bist_pm_p>;
    reg = <REG_CKG_PM_HIGH_EXT_BASE 0x4>;
    mux-shift = <2>;  //2+REG_CKG_PM_HIGH_EXT_OFFSET
    mux-width = <2>;
    gate-shift = <0>;  //0+REG_CKG_PM_HIGH_EXT_OFFSET
    ignore = <1>;
};

CLK_pm_pwm: CLK_pm_pwm {
    #clock-cells = <0>;
    compatible = "sstar,composite-clock";
    clocks = <&CLK_12m_mux>;
    reg = <REG_CKG_PM_PWM_BASE 0x4>;
    mux-shift = <12>;  //2+REG_CKG_PM_PWM_OFFSET
    mux-width = <2>;
    gate-shift = <10>;  //0+REG_CKG_PM_PWM_OFFSET
    ignore = <1>;
#if !IS_ENABLED (CONFIG_SSTAR_PWM)
    status = "disabled";
#endif
};

CLK_pm_uart0: CLK_pm_uart0 {
    #clock-cells = <0>;
    compatible = "sstar,composite-clock";
    clocks = <&CLK_24m_mux>;
    reg = <REG_CKG_PM_UART_BASE 0x4>;
    mux-shift = <2>;  //2+REG_CKG_PM_UART_OFFSET
    mux-width = <2>;
    gate-shift = <0>;  //0+REG_CKG_PM_UART_OFFSET
    ignore = <1>;
};

CLK_pm_fuart0: CLK_pm_fuart0 {
    #clock-cells = <0>;
    compatible = "sstar,composite-clock";
    clocks = <&CLK_24m_mux>;
    reg = <REG_CKG_PM_FUART0_BASE 0x4>;
    mux-shift = <10>;  //2+REG_CKG_PM_FUART0_OFFSET
    mux-width = <2>;
    gate-shift = <8>;  //0+REG_CKG_PM_FUART0_OFFSET
    ignore = <1>;
};

CLK_pm_fuart1: CLK_pm_fuart1 {
    #clock-cells = <0>;
    compatible = "sstar,composite-clock";
    clocks = <&CLK_24m_mux>;
    reg = <REG_CKG_PM_FUART1_BASE 0x4>;
    mux-shift = <14>;  //2+REG_CKG_PM_FUART1_OFFSET
    mux-width = <2>;
    gate-shift = <12>;  //0+REG_CKG_PM_FUART1_OFFSET
    ignore = <1>;
};

CLK_pm_miic0: CLK_pm_miic0 {
    #clock-cells = <0>;
    compatible = "sstar,composite-clock";
    clocks = <&CLK_24m_mux>;
    reg = <REG_CKG_PM_MIIC0_BASE 0x4>;
    mux-shift = <2>;  //2+REG_CKG_PM_MIIC0_OFFSET
    mux-width = <2>;
    gate-shift = <0>;  //0+REG_CKG_PM_MIIC0_OFFSET
    auto-enable = <0>;
};

CLK_pm_pwr_ctl: CLK_pm_pwr_ctl {
    #clock-cells = <0>;
    compatible = "sstar,composite-clock";
    clocks = <&CLK_24m_mux>;
    reg = <REG_CKG_PM_PWR_CTL_BASE 0x4>;
    mux-shift = <2>;  //2+REG_CKG_PM_PWR_CTL_OFFSET
    mux-width = <2>;
    gate-shift = <0>;  //0+REG_CKG_PM_PWR_CTL_OFFSET
    ignore = <1>;
};

CLK_mcu_pm: CLK_mcu_pm {
    #clock-cells = <0>;
    compatible = "sstar,composite-clock";
    clocks = <&CLK_source_mux_250m>,<&CLK_24m_mux>,<&CLK_source_mux_250m_div5>,<&CLK_source_mux_250m_div2>,<&CLK_xtali_12m>;
    reg = <REG_CKG_PM_MCU_BASE 0x4>;
    mux-shift = <2>;  //2+REG_CKG_PM_MCU_OFFSET
    mux-width = <2>;
    gate-shift = <0>;  //0+REG_CKG_PM_MCU_OFFSET
    glitch-shift = <4>;  //4+REG_CKG_PM_MCU_OFFSET
    auto-enable = <1>;
    str-ignore;
};

CLK_pm_sleep: CLK_pm_sleep {
    #clock-cells = <0>;
    compatible = "sstar,composite-clock";
    clocks = <&CLK_12m_mux>;
    reg = <REG_CKG_PM_SLEEP_BASE 0x4>;
    mux-shift = <12>;  //2+REG_CKG_PM_SLEEP_OFFSET
    mux-width = <2>;
    gate-shift = <10>;  //0+REG_CKG_PM_SLEEP_OFFSET
    ignore = <1>;
};

CLK_sar: CLK_sar {
    #clock-cells = <0>;
    compatible = "sstar,composite-clock";
    clocks = <&CLK_12m_mux>;
    reg = <REG_CKG_SAR_BASE 0x4>;
    mux-shift = <7>;  //2+REG_CKG_SAR_OFFSET
    mux-width = <2>;
    gate-shift = <5>;  //0+REG_CKG_SAR_OFFSET
    ignore = <1>;
};

CLK_rtc: CLK_rtc {
    #clock-cells = <0>;
    compatible = "sstar,composite-clock";
    clocks = <&CLK_12m_mux>;
    reg = <REG_CKG_RTC_BASE 0x4>;
    mux-shift = <2>;  //2+REG_CKG_RTC_OFFSET
    mux-width = <2>;
    gate-shift = <0>;  //0+REG_CKG_RTC_OFFSET
    ignore = <1>;
};

CLK_ir: CLK_ir {
    #clock-cells = <0>;
    compatible = "sstar,composite-clock";
    clocks = <&CLK_12m_mux>;
    reg = <REG_CKG_IR_BASE 0x4>;
    mux-shift = <7>;  //2+REG_CKG_IR_OFFSET
    mux-width = <2>;
    gate-shift = <5>;  //0+REG_CKG_IR_OFFSET
    ignore = <1>;
};

CLK_wdt: CLK_wdt {
    #clock-cells = <0>;
    compatible = "sstar,composite-clock";
    clocks = <&CLK_24m_mux>;
    reg = <REG_CKG_WDT_BASE 0x4>;
    mux-shift = <6>;  //2+REG_CKG_WDT_OFFSET
    mux-width = <2>;
    gate-shift = <4>;  //0+REG_CKG_WDT_OFFSET
    glitch-shift = <8>;  //4+REG_CKG_WDT_OFFSET
    ignore = <1>;
};

CLK_pm_sdio: CLK_pm_sdio {
    #clock-cells = <0>;
    compatible = "sstar,composite-clock";
    clocks = <&CLK_source_mux_250m_div4>,<&CLK_source_mux_250m_div6>,<&CLK_12m_mux_div40>,<&CLK_source_mux_250m>,<&CLK_xtali_12m>;
    reg = <REG_CKG_PM_SDIO_BASE 0x4>;
    mux-shift = <13>;  //2+REG_CKG_PM_SDIO_OFFSET
    mux-width = <2>;
    gate-shift = <11>;  //0+REG_CKG_PM_SDIO_OFFSET
    glitch-shift = <15>;  //5+REG_CKG_PM_SDIO_OFFSET
    ignore = <1>;
};

CLK_pir_pm: CLK_pir_pm {
    #clock-cells = <0>;
    compatible = "sstar,composite-clock";
    clocks = <&CLK_24m_mux>;
    reg = <REG_CKG_PIR_PM_BASE 0x4>;
    mux-shift = <7>;  //2+REG_CKG_PIR_PM_OFFSET
    mux-width = <2>;
    gate-shift = <5>;  //0+REG_CKG_PIR_PM_OFFSET
    ignore = <1>;
};

CLK_pm_sr_mclk: CLK_pm_sr_mclk {
    #clock-cells = <0>;
    compatible = "sstar,composite-clock";
    clocks = <&CLK_source_mux_250m_div8>,<&CLK_24m_mux>,<&CLK_12m_mux>,<&CLK_12m_mux_div2>;
    reg = <REG_CKG_PM_SR_MCLK_BASE 0x4>;
    mux-shift = <10>;  //2+REG_CKG_PM_SR_MCLK_OFFSET
    mux-width = <2>;
    gate-shift = <8>;  //0+REG_CKG_PM_SR_MCLK_OFFSET
    ignore = <1>;
};

CLK_ssi_dphy: CLK_ssi_dphy {
    #clock-cells = <0>;
    compatible = "sstar,composite-clock";
    clocks = <&CLK_source_mux_250m>,<&CLK_source_mux_250m_div2>,<&CLK_source_mux_250m_div4>,<&CLK_24m_mux>;
    reg = <REG_CKG_SSI_DPHY_BASE 0x4>;
    mux-shift = <6>;  //2+REG_CKG_SSI_DPHY_OFFSET
    mux-width = <2>;
    gate-shift = <4>;  //0+REG_CKG_SSI_DPHY_OFFSET
    ignore = <1>;
};

CLK_pm_timer4: CLK_pm_timer4 {
    #clock-cells = <0>;
    compatible = "sstar,complex-clock";
    clocks = <&CLK_12m_mux>;
    clock-frequency = <12000000>;
};

CLK_pm_timer5: CLK_pm_timer5 {
    #clock-cells = <0>;
    compatible = "sstar,complex-clock";
    clocks = <&CLK_12m_mux>;
    clock-frequency = <12000000>;
};

CLK_pm_timer6: CLK_pm_timer6 {
    #clock-cells = <0>;
    compatible = "sstar,complex-clock";
    clocks = <&CLK_12m_mux>;
    clock-frequency = <12000000>;
};

CLK_pm_timer7: CLK_pm_timer7 {
    #clock-cells = <0>;
    compatible = "sstar,complex-clock";
    clocks = <&CLK_12m_mux>;
    clock-frequency = <12000000>;
};

CLK_upll_48m: CLK_upll_48m {
    #clock-cells = <0>;
    compatible = "sstar,complex-clock";
    clocks = <&CLK_upll_960m>;
};

/* for clock must be added by hand end */

CLK_wdma: CLK_wdma {
    #clock-cells = <0>;
    compatible = "sstar,composite-clock";
    clocks = <&CLK_miu_p>;
    reg = <REG_DBG_WDMA_CLK_MIU_CKG_BASE 0x4>;
    gate-shift = <0>;  //0+REG_DBG_WDMA_CLK_MIU_CKG_OFFSET
    gate-enable = <1>;
    auto-enable = <0>;
};

CLK_miu_boot: CLK_miu_boot {
    #clock-cells = <0>;
    compatible = "sstar,composite-clock";
    clocks = <&CLK_xtali_12m>,<&CLK_mpll_288m>;
    reg = <REG_CKG_MIU_BOOT_BASE 0x4>;
    mux-shift = <2>;  //2+REG_CKG_MIU_BOOT_OFFSET
    mux-width = <1>;
    gate-shift = <0>;  //0+REG_CKG_MIU_BOOT_OFFSET
    auto-enable = <0>;
};

CLK_upll_960m: CLK_upll_960m {
    #clock-cells = <0>;
    compatible = "sstar,complex-clock";
    clocks = <&CLK_xtali_24m>;
    str-ignore;
};

#ifdef CONFIG_SSTAR_CLK_OS_MANAGE
clk_os_manage: clk_os_manage {
    compatible = "sstar,clk-os-manage";
    clocks = <&CLK_VOID>,
             <&CLK_upll_480m>,
             <&CLK_mpll_432m>,
             <&CLK_upll_384m>,
             <&CLK_mpll_345m>,
             <&CLK_upll_320m>,
             <&CLK_mpll_288m>,
             <&CLK_mpll_216m>,
             <&CLK_mpll_172m>,
             <&CLK_mpll_123m>,
             <&CLK_mpll_86m>,
             <&CLK_upll_480m_div2>,
             <&CLK_upll_384m_div2>,
             <&CLK_upll_320m_div2>,
             <&CLK_mpll_288m_div2>,
             <&CLK_mpll_288m_div4>,
             <&CLK_mpll_288m_div8>,
             <&CLK_mpll_432m_div4>,
             <&CLK_mpll_432m_div8>,
             <&CLK_mpll_432m_div16>,
             <&CLK_mpll_123m_div2>,
             <&CLK_mpll_86m_div2>,
             <&CLK_mpll_86m_div4>,
             <&CLK_mpll_86m_div16>,
             <&CLK_upll_384m_div8>,
             <&CLK_upll_320m_div8>,
             <&CLK_upll_320m_div10>,
             <&CLK_upll_320m_div16>,
             <&CLK_disppll_clk>,
             <&CLK_disppll_clk_div2>,
             <&CLK_xtali_12m>,
             <&CLK_xtali_12m_div8>,
             <&CLK_xtali_12m_div16>,
             <&CLK_xtali_12m_div40>,
             <&CLK_xtali_12m_div64>,
             <&CLK_xtali_12m_div128>,
             <&CLK_xtali_24m>,
             <&CLK_CLK_12M_CORE_v_live>,
             <&CLK_ipupll_clk>,
             <&CLK_miupll_clk>,
             <&CLK_cpu_pll>,
             <&CLK_armpll_37p125m>,
             <&CLK_spi_synth_pll>,
             <&CLK_fuart_synth_out>,
             <&CLK_fuart0_synth_out>,
             <&CLK_fuart1_synth_out>,
             <&CLK_miu_p>,
             <&CLK_mspi0_p>,
             <&CLK_mcu_p>,
             <&CLK_mcu_pm_p>,
             <&CLK_otp_p>,
             <&CLK_bist_pm_p>,
             <&CLK_emac_testrx125_in_lan>,
             <&CLK_source_mux_250m>,
             <&CLK_source_mux_250m_div2>,
             <&CLK_source_mux_250m_div4>,
             <&CLK_source_mux_250m_div5>,
             <&CLK_source_mux_250m_div6>,
             <&CLK_source_mux_250m_div8>,
             <&CLK_12m_mux>,
             <&CLK_12m_mux_div2>,
             <&CLK_12m_mux_div40>,
             <&CLK_24m_mux>,
             <&CLK_ddr_syn>,
             <&CLK_miu_rec>,
             <&CLK_mcu>,
             <&CLK_riubrdg>,
             <&CLK_pwm>,
             <&CLK_fuart_synth_in>,
             <&CLK_fuart0_synth_in>,
             <&CLK_fuart1_synth_in>,
             <&CLK_fuart>,
             <&CLK_fuart0>,
             <&CLK_fuart1>,
             <&CLK_mspi0>,
             <&CLK_miic0>,
             <&CLK_miic1>,
             <&CLK_miic2>,
             <&CLK_pwr_ctl>,
             <&CLK_xtali>,
             <&CLK_live_c>,
             <&CLK_live>,
             <&CLK_sr00_mclk>,
             <&CLK_sr01_mclk>,
             <&CLK_ipu>,
             <&CLK_ipuff>,
             <&CLK_hemcu>,
             <&CLK_csi0_mac_lptx_top_i>,
             <&CLK_csi0_mac_top_i>,
             <&CLK_csi0_ns_top_i>,
             <&CLK_csi1_mac_lptx_top_i>,
             <&CLK_csi1_mac_top_i>,
             <&CLK_csi1_ns_top_i>,
             <&CLK_vhe>,
             <&CLK_mfe>,
             <&CLK_ven_axi>,
             <&CLK_ven_scdn>,
             <&CLK_ven_sc_if>,
             <&CLK_xtali_sc_gp>,
             <&CLK_jpe>,
             <&CLK_aesdma>,
             <&CLK_sd>,
             <&CLK_fsp_qspi>,
             <&CLK_bist_isp_gp>,
             <&CLK_isp>,
             <&CLK_dsc_enc1>,
             <&CLK_dsc_dec1>,
             <&CLK_fclk1>,
             <&CLK_disp_pixel_0>,
             <&CLK_ive>,
             <&CLK_ldcfeye>,
             <&CLK_emac_ahb>,
             <&CLK_au_sys_384>,
             <&CLK_au_sys_432>,
             <&CLK_otp>,
             <&CLK_real_live>,
             <&CLK_spi_nonpm>,
             <&CLK_pm_high_ext>,
             <&CLK_pm_pwm>,
             <&CLK_pm_uart0>,
             <&CLK_pm_fuart0>,
             <&CLK_pm_fuart1>,
             <&CLK_pm_miic0>,
             <&CLK_pm_pwr_ctl>,
             <&CLK_mcu_pm>,
             <&CLK_pm_sleep>,
             <&CLK_sar>,
             <&CLK_rtc>,
             <&CLK_ir>,
             <&CLK_wdt>,
             <&CLK_pm_sdio>,
             <&CLK_pir_pm>,
             <&CLK_pm_sr_mclk>,
             <&CLK_ssi_dphy>,
             <&CLK_pm_timer4>,
             <&CLK_pm_timer5>,
             <&CLK_pm_timer6>,
             <&CLK_pm_timer7>,
             <&CLK_upll_48m>,
             <&CLK_wdma>,
             <&CLK_miu_boot>,
             <&CLK_upll_960m>;
    clock-count = <142>;
};
#endif
